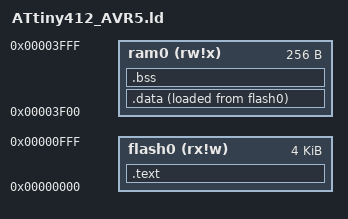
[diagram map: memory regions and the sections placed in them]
/*
 * This file was auto-generated by microzig
 *
 * Target CPU:  AVR5
 * Target Chip: ATtiny412
 */

ENTRY(microzig_main);

MEMORY
{
  flash0 (rx!w) : ORIGIN = 0x00000000, LENGTH = 0x00001000
  ram0   (rw!x) : ORIGIN = 0x00003F00, LENGTH = 0x00000100
}

SECTIONS
{
  .text :
  {
     KEEP(*(microzig_flash_start))
     *(.text*)
  } > flash0

  .data :
  {
     microzig_data_start = .;
     *(.rodata*)
     *(.data*)
     microzig_data_end = .;
  } > ram0 AT> flash0

  .bss (NOLOAD) :
  {
      microzig_bss_start = .;
      *(.bss*)
      microzig_bss_end = .;
  } > ram0

  microzig_data_load_start = LOADADDR(.data);
}
